# A31G11x register map
Vendor: VENDOR ABOV Semiconductor Co., Ltd.; Series: A31G11x; File version: 1.0
CPU: CM0+ r0p1, little endian, no MPU, no FPU, VTOR, 2 interrupt priority bits
Registers are 32-bit, read-write, reset 0x0 unless marked. A register's access mark holds for its fields unless they carry their own. Offsets are from the block's base; [hi:lo] are bit positions; {n}, {i} and the like mark numbered series.

## TIMER30 — Timer/Counter 30
Base 0x40002400
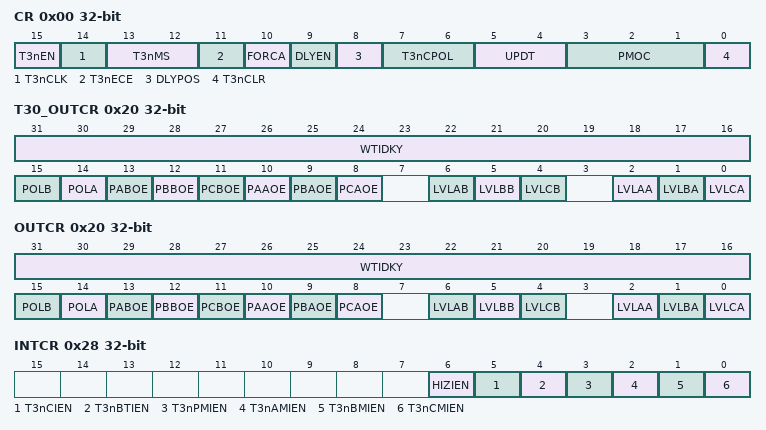
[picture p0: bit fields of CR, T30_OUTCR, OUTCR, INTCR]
0x00 CR — TIMER3n Control Register
  [15] T3nEN — TIMER3n Operation Enable
    0=Disable TIMER3n Operation; 1=Enable TIMER3n Operation. (Counter Clear and Start)
  [14] T3nCLK — TIMER3n Clock Selection
    0=IntPrescaledClock (Select an Internal Prescaler Clock.); 1=ExtClock (Select an External Clock.)
  [13:12] T3nMS — TIMER3n Operation Mode Selection
    0=Interval mode. (All match interrupts can occur); 1=Capture mode. (The Period-match interrupt can occur); 2=Back-to-back mode. (All interrupts can occur)
  [11] T3nECE — TIMER3n External Clock Edge Selection
    0=FallingEdge (Select falling edge of external clock.); 1=RisingEdge (Select rising edge of external clock.)
  [10] FORCA — TIMER3n Output Mode SelectionSelection. This bit should be changed while T3nEN is '0'.
    0=AllChannelMode (6-Channel mode. (The PWM3nxA/PWM3nxB pins are outputs according to the TIMER30_xDR registers, respectively.)); 1=AChannelMode (Force A-Channel mode. (All PWM3nxA/PWM3nxB pins are outputs according only to the TIMER30_ADR register.))
  [9] DLYEN — Delay Time Insertion Enable
    0=Disable delay time insertion to the PWM3nxA/PWM3nxB; 1=Enable delay time insertion to the PWM3nxA/PWM3nxB
  [8] DLYPOS — Delay Time Insertion Position
    0=FrontABehindB (Insert in front of PWM3nxA and behind PWM3nxB pins.); 1=BehindAFrontB (Insert behind PWM3nxA and in front of PWM3nxB pins.)
  [7:6] T3nCPOL — TIMER3n Capture Polarity Selection
    0=FallingEdge (Capture on falling edge.); 1=RisingEdge (Capture on rising edge.); 2=BothEdge (Capture on both falling and rising edge.)
  [5:4] UPDT — Data Reload Time Selection
    0=AtWriting (Update data to buffer at the time of writing.); 1=AtPeriodMatch (Update data to buffer at period match.); 2=AtBottom (Update data to buffer at bottom.)
  [3:1] PMOC — Period Match Interrupt Occurrence Selection
    {v}=Every{v+1}PeriodMatch (Once every {v+1} period match.) (v=0..7)
  [0] T3nCLR — TIMER3n Counter and Prescaler Clear
    0=NoEffect; 1=Clear TIMER3n counter and prescaler. (Automatically cleared to '0b' after operation)
0x04 PDR reset 0xFFFF — TIMER3n Period Data Register
  [15:0] PDATA — TIMER3n Period Data
0x08 ADR reset 0xFFFF — TIMER3n A Data Register
  [15:0] ADATA — TIMER3n A Data
0x0C BDR reset 0xFFFF — TIMER3n B Data Register
  [15:0] BDATA — TIMER3n B Data
0x10 CDR reset 0xFFFF — TIMER3n C Data Register
  [15:0] CDATA — TIMER3n C Data
0x14 CAPDR ro — TIMER3n Capture Data Register
  [15:0] CAPD — TIMER3n Capture Data
0x18 PREDR reset 0xFFF — TIMER3n Prescaler Data Register
  [11:0] PRED — TIMER3n Prescaler Data
0x1C CNT ro — TIMER3n Counter Register
  [15:0] CNT — TIMER3n Counter
0x20 T30_OUTCR (alternate view of OUTCR) — TIMER3n Output Control Register
  [31:16] WTIDKY wo — Write Identification Key (0xe06c)
    0xE06C=Value (Key Value (0xe06c))
  [15] POLB — PWM3nxB Output Polarity Selection
  [14] POLA — PWM3nxA Output Polarity Selection
  [13] PABOE — PWM3nAB Output Enable
  [12] PBBOE — PWM3nBB Output Enable
  [11] PCBOE — PWM3nCB Output Enable
  [10] PAAOE — PWM3nAA Output Enable
  [9] PBAOE — PWM3nBA Output Enable
  [8] PCAOE — PWM3nCA Output Enable
  [6] LVLAB — Configure PWM3nAB Output when Disable
  [5] LVLBB — Configure PWM3nBB Output when Disable
  [4] LVLCB — Configure PWM3nCB Output when Disable
  [2] LVLAA — Configure PWM3nAA Output when Disable
  [1] LVLBA — Configure PWM3nBA Output when Disable
  [0] LVLCA — Configure PWM3nCA Output when Disable
0x20 OUTCR — TIMER3n Output Control Register
  [31:16] WTIDKY wo — Write Identification Key
  [15] POLB — PWM3nxB Output Polarity Selection
    0=StartLow (Low level start. (The PWM3nxB pins are started with low level after counting.)); 1=StartHigh (High level start. (The PWM3nxB pins are started with high level after counting))
  [14] POLA — PWM3nxA Output Polarity Selection
    0=StartLow (Low level start. (The PWM3nxA pins are started with low level after counting.)); 1=StartHigh (High level start. (The PWM3nxA pins are started with high level after counting))
  [13] PABOE — PWM3nAB Output Enable
    0=Disable output; 1=Enable output
  [12] PBBOE — PWM3nBB Output Enable
    0=Disable output; 1=Enable output
  [11] PCBOE — PWM3nCB Output Enable
    0=Disable output; 1=Enable output
  [10] PAAOE — PWM3nAA Output Enable
    0=Disable output; 1=Enable output
  [9] PBAOE — PWM3nBA Output Enable
    0=Disable output; 1=Enable output
  [8] PCAOE — PWM3nCA Output Enable
    0=Disable output; 1=Enable output
  [6] LVLAB — Configure PWM3nAB Output when Disable
    0=Low (Low level.); 1=High level
  [5] LVLBB — Configure PWM3nBB Output when Disable
    0=Low (Low level.); 1=High level
  [4] LVLCB — Configure PWM3nCB Output when Disable
    0=Low (Low level.); 1=High level
  [2] LVLAA — Configure PWM3nAA Output when Disable
    0=Low (Low level.); 1=High level
  [1] LVLBA — Configure PWM3nBA Output when Disable
    0=Low (Low level.); 1=High level
  [0] LVLCA — Configure PWM3nCA Output when Disable
    0=Low (Low level.); 1=High level
0x24 DLY — TIMER3n PWM Output Delay Data Register
  [9:0] DLY — TIMER3n PWM Delay Data
0x28 INTCR — TIMER3n Interrupt Control Register
  [6] HIZIEN — TIMER3n Output High-Impedance Interrupt Enable
    0=Disable TIMER3n output high-impedance interrupt; 1=Enable TIMER3n output high-impedance interrupt
  [5] T3nCIEN — TIMER3n Capture Interrupt Enable
    0=Disable TIMER3n capture interrupt; 1=Enable TIMER3n capture interrupt
  [4] T3nBTIEN — TIMER3n Bottom Interrupt Enable
    0=Disable TIMER3n bottom interrupt; 1=Enable TIMER3n bottom interrupt
  [3] T3nPMIEN — TIMER3n Period Match Interrupt Enable
    0=Disable TIMER3n period interrupt; 1=Enable TIMER3n period interrupt
  [2] T3nAMIEN — TIMER3n A-ch Match Interrupt Enable
    0=Disable TIMER3n A-ch match interrupt; 1=Enable TIMER3n A-ch match interrupt
  [1] T3nBMIEN — TIMER3n B-ch Match Interrupt Enable
    0=Disable TIMER3n B-ch match interrupt; 1=Enable TIMER3n B-ch match interrupt
  [0] T3nCMIEN — TIMER3n C-ch Match Interrupt Enable
    0=Disable TIMER3n C-ch match interrupt; 1=Enable TIMER3n C-ch match interrupt
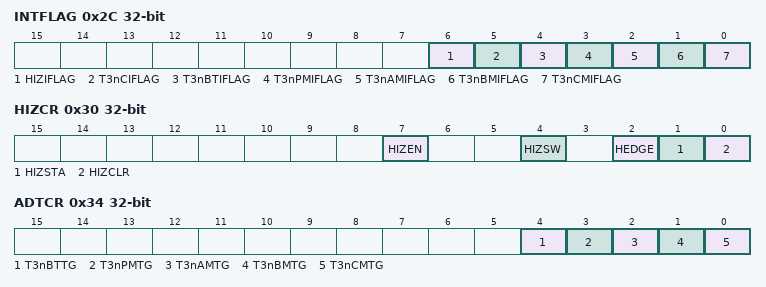
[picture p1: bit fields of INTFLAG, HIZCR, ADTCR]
0x2C INTFLAG — TIMER3n Interrupt Flag Register
  [all] fields
    0=No request occurred; 1=Request occurred. The bit will be cleared to '0' when '1' is written to this bit.
  [6] HIZIFLAG — TIMER3n Output High-Impedance Interrupt Flag
  [5] T3nCIFLAG — TIMER3n Capture Interrupt Flag
  [4] T3nBTIFLAG — TIMER3n Bottom Interrupt Flag
  [3] T3nPMIFLAG — TIMER3n Period Match Interrupt Flag
  [2] T3nAMIFLAG — TIMER3n A-ch Match Interrupt Flag
  [1] T3nBMIFLAG — TIMER3n B-ch Match Interrupt Flag
  [0] T3nCMIFLAG — TIMER3n C-ch Match Interrupt Flag
0x30 HIZCR — TIMER3n High-Impedance Control Register
  [7] HIZEN — PWM3nxA/PWM3nxB Output High-Impedance Enable
    0=Disable to control the output high-impedance; 1=Enable to control the output high-impedance
  [4] HIZSW — High-Impedance Output Software Setting
    0=NoEffect; 1=HiZ (PWM3nxA/PWM3nxB pins go into high impedance. (Automatically cleared to '0' after operation))
  [2] HEDGE — High-Impedance Edge Selection
    0=Falling edge of the BLNK pin; 1=Rising edge of the BLNK pin
  [1] HIZSTA ro — High-Impedance Status
    0=NoHiZ (Indicates that the pins are not under a Hi-Z state.); 1=HiZ (Indicates that the pins are under a Hi-Z state.)
  [0] HIZCLR — High-Impedance Output Clear
    0=NoEffect; 1=Clear high-impedance output. (The PWM3nxA/PWM3nxB pins returns as output and this bit is automatically cleared to '0' after operation.)
0x34 ADTCR — TIMER3n ADC Trigger Control Register
  [4] T3nBTTG — Select TIMER3n Bottom for ADC Trigger Signal Generator.
    0=Disable ADC trigger signal generator by bottom; 1=Enable ADC trigger signal generator by bottom
  [3] T3nPMTG — Select TIMER3n Period Match for ADC Trigger Signal Generator.
    0=Disable ADC trigger signal generator by period match; 1=Enable ADC trigger signal generator by period match
  [2] T3nAMTG — Select TIMER3n A-ch Match for ADC Trigger Signal Generator.
    0=Disable ADC trigger signal generator by A-ch match; 1=Enable ADC trigger signal generator by A-ch match
  [1] T3nBMTG — Select TIMER3n B-ch Match for ADC Trigger Signal Generator.
    0=Disable ADC trigger signal generator by B-ch match; 1=Enable ADC trigger signal generator by B-ch match
  [0] T3nCMTG — Select TIMER3n C-ch Match for ADC Trigger Signal Generator.
    0=Disable ADC trigger signal generator by C-ch match; 1=Enable ADC trigger signal generator by C-ch match
0x38 ADTDR — TIMER3n ADC Trigger Generator Data Register
  [13:0] ADTDATA — TIMER3n ADC Trigger Generation Data
